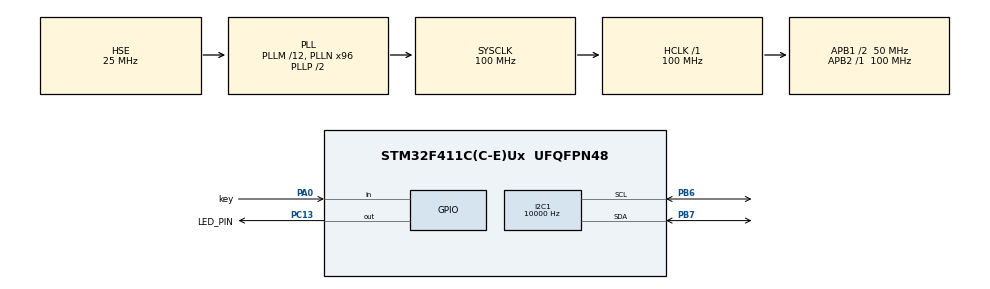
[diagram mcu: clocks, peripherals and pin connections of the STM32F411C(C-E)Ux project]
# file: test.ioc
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I2C1.ClockSpeed=10000
Mcu.Family=STM32F4
Mcu.Name=STM32F411C(C-E)Ux
Mcu.Package=UFQFPN48
NVIC.PriorityGroup=NVIC_PRIORITYGROUP_4
NVIC.TIM1_UP_TIM10_IRQn=true\:0\:0\:false\:false\:true\:true\:true\:true
PA0-WKUP.GPIO_Label=key
PA0-WKUP.GPIO_PuPd=GPIO_PULLUP
PA0-WKUP.Signal=GPIO_Input
PA13.Mode=Serial_Wire
PA13.Signal=SYS_JTMS-SWDIO
PA14.Mode=Serial_Wire
PA14.Signal=SYS_JTCK-SWCLK
PB6.GPIO_Pu=GPIO_PULLUP
PB6.Mode=I2C
PB6.Signal=I2C1_SCL
PB7.GPIO_Pu=GPIO_PULLUP
PB7.Mode=I2C
PB7.Signal=I2C1_SDA
PC13-ANTI_TAMP.GPIO_Label=LED_PIN
PC13-ANTI_TAMP.Signal=GPIO_Output
PH0\ -\ OSC_IN.Mode=HSE-External-Oscillator
PH0\ -\ OSC_IN.Signal=RCC_OSC_IN
PH1\ -\ OSC_OUT.Mode=HSE-External-Oscillator
PH1\ -\ OSC_OUT.Signal=RCC_OSC_OUT
ProjectManager.HeapSize=0x200
ProjectManager.StackSize=0x400
ProjectManager.TargetToolchain=STM32CubeIDE
RCC.48MHZClocksFreq_Value=50000000
RCC.AHBFreq_Value=100000000
RCC.APB1CLKDivider=RCC_HCLK_DIV2
RCC.APB1Freq_Value=50000000
RCC.APB1TimFreq_Value=100000000
RCC.APB2Freq_Value=100000000
RCC.APB2TimFreq_Value=100000000
RCC.CortexFreq_Value=100000000
RCC.HCLKFreq_Value=100000000
RCC.HSE_VALUE=25000000
RCC.HSI_VALUE=16000000
RCC.LSE_VALUE=32768
RCC.PLLM=12
RCC.PLLN=96
RCC.PLLSourceVirtual=RCC_PLLSOURCE_HSE
RCC.SYSCLKFreq_VALUE=100000000
RCC.SYSCLKSource=RCC_SYSCLKSOURCE_PLLCLK
RCC.VCOOutputFreq_Value=200000000
TIM1.AutoReloadPreload=TIM_AUTORELOAD_PRELOAD_ENABLE
TIM1.Period=1000
TIM1.Prescaler=99
VP_TIM1_VS_ClockSourceINT.Mode=Internal
board=custom

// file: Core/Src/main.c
/* USER CODE BEGIN Header */
/**
  ******************************************************************************
  * @file           : main.c
  * @brief          : Main program body
  ******************************************************************************
  * @attention
  *
  * Copyright (c) 2023 STMicroelectronics.
  * All rights reserved.
  *
  * This software is licensed under terms that can be found in the LICENSE file
  * in the root directory of this software component.
  * If no LICENSE file comes with this software, it is provided AS-IS.
  *
  ******************************************************************************
  */
/* USER CODE END Header */
#include "main.h"

/* USER CODE BEGIN Includes */
#include "led.h"
#include "key.h"
#include "eeprom.h"
/* USER CODE END Includes */

I2C_HandleTypeDef hi2c1;

TIM_HandleTypeDef htim1;

/* USER CODE BEGIN PV */

uint8_t schedulerOn = 0;
/* USER CODE END PV */

void SystemClock_Config(void);
static void MX_GPIO_Init(void);
static void MX_I2C1_Init(void);
static void MX_TIM1_Init(void);

int main(void)
{

  /* MCU Configuration--------------------------------------------------------*/

  /* Reset of all peripherals, Initializes the Flash interface and the Systick. */
  HAL_Init();

  /* Configure the system clock */
  SystemClock_Config();

  /* Initialize all configured peripherals */
  MX_GPIO_Init();
  MX_I2C1_Init();
  MX_TIM1_Init();
  /* USER CODE BEGIN 2 */
  HAL_TIM_Base_Start_IT(&htim1);
  /* USER CODE END 2 */

  /* Infinite loop */
  while (1)
  {

    /* USER CODE BEGIN 3 */
	//HAL_Delay(50);
	  while(schedulerOn == 0);
	  schedulerOn = 0;
	  ledTask();
	  keyTask();
	  eepromTask();
  }
  /* USER CODE END 3 */
}

void SystemClock_Config(void)
{
  RCC_OscInitTypeDef RCC_OscInitStruct = {0};
  RCC_ClkInitTypeDef RCC_ClkInitStruct = {0};

  /** Configure the main internal regulator output voltage
  */
  __HAL_RCC_PWR_CLK_ENABLE();
  __HAL_PWR_VOLTAGESCALING_CONFIG(PWR_REGULATOR_VOLTAGE_SCALE1);

  /** Initializes the RCC Oscillators according to the specified parameters
  * in the RCC_OscInitTypeDef structure.
  */
  RCC_OscInitStruct.OscillatorType = RCC_OSCILLATORTYPE_HSE;
  RCC_OscInitStruct.HSEState = RCC_HSE_ON;
  RCC_OscInitStruct.PLL.PLLState = RCC_PLL_ON;
  RCC_OscInitStruct.PLL.PLLSource = RCC_PLLSOURCE_HSE;
  RCC_OscInitStruct.PLL.PLLM = 12;
  RCC_OscInitStruct.PLL.PLLN = 96;
  RCC_OscInitStruct.PLL.PLLP = RCC_PLLP_DIV2;
  RCC_OscInitStruct.PLL.PLLQ = 4;
  if (HAL_RCC_OscConfig(&RCC_OscInitStruct) != HAL_OK)
  {
    Error_Handler();
  }

  /** Initializes the CPU, AHB and APB buses clocks
  */
  RCC_ClkInitStruct.ClockType = RCC_CLOCKTYPE_HCLK|RCC_CLOCKTYPE_SYSCLK
                              |RCC_CLOCKTYPE_PCLK1|RCC_CLOCKTYPE_PCLK2;
  RCC_ClkInitStruct.SYSCLKSource = RCC_SYSCLKSOURCE_PLLCLK;
  RCC_ClkInitStruct.AHBCLKDivider = RCC_SYSCLK_DIV1;
  RCC_ClkInitStruct.APB1CLKDivider = RCC_HCLK_DIV2;
  RCC_ClkInitStruct.APB2CLKDivider = RCC_HCLK_DIV1;

  if (HAL_RCC_ClockConfig(&RCC_ClkInitStruct, FLASH_LATENCY_3) != HAL_OK)
  {
    Error_Handler();
  }
}

static void MX_I2C1_Init(void)
{

  hi2c1.Instance = I2C1;
  hi2c1.Init.ClockSpeed = 10000;
  hi2c1.Init.DutyCycle = I2C_DUTYCYCLE_2;
  hi2c1.Init.OwnAddress1 = 0;
  hi2c1.Init.AddressingMode = I2C_ADDRESSINGMODE_7BIT;
  hi2c1.Init.DualAddressMode = I2C_DUALADDRESS_DISABLE;
  hi2c1.Init.OwnAddress2 = 0;
  hi2c1.Init.GeneralCallMode = I2C_GENERALCALL_DISABLE;
  hi2c1.Init.NoStretchMode = I2C_NOSTRETCH_DISABLE;
  if (HAL_I2C_Init(&hi2c1) != HAL_OK)
  {
    Error_Handler();
  }

}

static void MX_TIM1_Init(void)
{

  TIM_ClockConfigTypeDef sClockSourceConfig = {0};
  TIM_MasterConfigTypeDef sMasterConfig = {0};

  htim1.Instance = TIM1;
  htim1.Init.Prescaler = 99;
  htim1.Init.CounterMode = TIM_COUNTERMODE_UP;
  htim1.Init.Period = 1000;
  htim1.Init.ClockDivision = TIM_CLOCKDIVISION_DIV1;
  htim1.Init.RepetitionCounter = 0;
  htim1.Init.AutoReloadPreload = TIM_AUTORELOAD_PRELOAD_ENABLE;
  if (HAL_TIM_Base_Init(&htim1) != HAL_OK)
  {
    Error_Handler();
  }
  sClockSourceConfig.ClockSource = TIM_CLOCKSOURCE_INTERNAL;
  if (HAL_TIM_ConfigClockSource(&htim1, &sClockSourceConfig) != HAL_OK)
  {
    Error_Handler();
  }
  sMasterConfig.MasterOutputTrigger = TIM_TRGO_RESET;
  sMasterConfig.MasterSlaveMode = TIM_MASTERSLAVEMODE_DISABLE;
  if (HAL_TIMEx_MasterConfigSynchronization(&htim1, &sMasterConfig) != HAL_OK)
  {
    Error_Handler();
  }

}

static void MX_GPIO_Init(void)
{
  GPIO_InitTypeDef GPIO_InitStruct = {0};

  /* GPIO Ports Clock Enable */
  __HAL_RCC_GPIOC_CLK_ENABLE();
  __HAL_RCC_GPIOH_CLK_ENABLE();
  __HAL_RCC_GPIOA_CLK_ENABLE();
  __HAL_RCC_GPIOB_CLK_ENABLE();

  /*Configure GPIO pin Output Level */
  HAL_GPIO_WritePin(LED_PIN_GPIO_Port, LED_PIN_Pin, GPIO_PIN_RESET);

  /*Configure GPIO pin : LED_PIN_Pin */
  GPIO_InitStruct.Pin = LED_PIN_Pin;
  GPIO_InitStruct.Mode = GPIO_MODE_OUTPUT_PP;
  GPIO_InitStruct.Pull = GPIO_NOPULL;
  GPIO_InitStruct.Speed = GPIO_SPEED_FREQ_LOW;
  HAL_GPIO_Init(LED_PIN_GPIO_Port, &GPIO_InitStruct);

  /*Configure GPIO pin : key_Pin */
  GPIO_InitStruct.Pin = key_Pin;
  GPIO_InitStruct.Mode = GPIO_MODE_INPUT;
  GPIO_InitStruct.Pull = GPIO_PULLUP;
  HAL_GPIO_Init(key_GPIO_Port, &GPIO_InitStruct);

}

/* USER CODE BEGIN 4 */
void HAL_TIM_PeriodElapsedCallback(TIM_HandleTypeDef *htim)
{
  /* Prevent unused argument(s) compilation warning */
  UNUSED(htim);
  schedulerOn = !0;
}

/* USER CODE END 4 */

void Error_Handler(void)
{
  __disable_irq();
  while (1)
  {
  }
}
